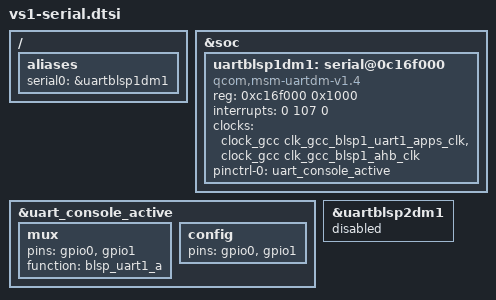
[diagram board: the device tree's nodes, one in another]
/* Copyright (c) 2017, Oculus VR. All rights reserved.
 *
 * This program is free software; you can redistribute it and/or modify
 * it under the terms of the GNU General Public License version 2 and
 * only version 2 as published by the Free Software Foundation.
 *
 * This program is distributed in the hope that it will be useful,
 * but WITHOUT ANY WARRANTY; without even the implied warranty of
 * MERCHANTABILITY or FITNESS FOR A PARTICULAR PURPOSE.  See the
 * GNU General Public License for more details.
 */


/ {
	aliases {
		serial0 = &uartblsp1dm1;
	};
};

&soc {
	/delete-node/ serial@0c170000;

	/* debug uart */
	uartblsp1dm1: serial@0c16f000 {
		compatible = "qcom,msm-uartdm-v1.4", "qcom,msm-uartdm";
		reg = <0xc16f000 0x1000>;
		interrupts = <0 107 0>;
		clocks = <&clock_gcc clk_gcc_blsp1_uart1_apps_clk>,
			<&clock_gcc clk_gcc_blsp1_ahb_clk>;
		clock-names = "core", "iface";
	};
};

&uart_console_active {
	mux {
		pins = "gpio0", "gpio1";
		function = "blsp_uart1_a";
	};

	config {
		pins = "gpio0", "gpio1";
	};
};

&uartblsp2dm1 {
	status = "disabled";
};

&uartblsp1dm1 {
	status = "ok";
	pinctrl-names = "default";
	pinctrl-0 = <&uart_console_active>;
};
